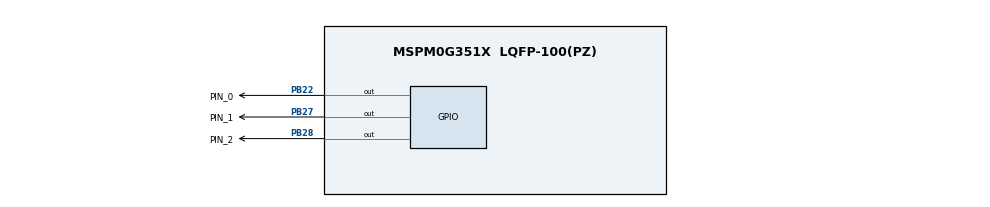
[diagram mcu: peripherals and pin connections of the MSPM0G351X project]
/**
 * @cliArgs --device "MSPM0G351X" --part "Default" --package "LQFP-100(PZ)" --product "mspm0_sdk@2.02.00.05"
 * @versions {"tool":"1.21.0+3721"}
 */

/**
 * Import the modules used in this configuration.
 */
const GPIO          = scripting.addModule("/ti/driverlib/GPIO", {}, false);
const GPIO1         = GPIO.addInstance();
const SYSCTL        = scripting.addModule("/ti/driverlib/SYSCTL");
const TIMER         = scripting.addModule("/ti/driverlib/TIMER", {}, false);
const TIMER1        = TIMER.addInstance();
const ProjectConfig = scripting.addModule("/ti/project_config/ProjectConfig");

/**
 * Write custom configuration values to the imported modules.
 */
GPIO1.$name                         = "GPIO_GRP_0";
GPIO1.associatedPins.create(3);
GPIO1.associatedPins[0].$name       = "PIN_0";
GPIO1.associatedPins[0].pin.$assign = "PB22";
GPIO1.associatedPins[1].$name       = "PIN_1";
GPIO1.associatedPins[1].pin.$assign = "PB27";
GPIO1.associatedPins[2].$name       = "PIN_2";
GPIO1.associatedPins[2].pin.$assign = "PB28";

const Board = scripting.addModule("/ti/driverlib/Board", {}, false);


TIMER1.$name            = "TIMER_0";
TIMER1.timerMode        = "PERIODIC";
TIMER1.timerClkPrescale = 32;
TIMER1.timerClkDiv      = 8;
TIMER1.timerPeriod      = "250 ms";
TIMER1.timerStartTimer  = true;
TIMER1.interrupts       = ["ZERO"];

ProjectConfig.deviceSpin = "MSPM0G3519";
ProjectConfig.genLinker  = false;
scripting.suppress("All four File Generation options must be enabled in order to guarantee Device Migration support\\. If an option is disabled, the user must manually configure that setting on its own file\\.", ProjectConfig);

/**
 * Pinmux solution for unlocked pins/peripherals. This ensures that minor changes to the automatic solver in a future
 * version of the tool will not impact the pinmux you originally saw.  These lines can be completely deleted in order to
 * re-solve from scratch.
 */
Board.peripheral.$suggestSolution          = "DEBUGSS";
Board.peripheral.swclkPin.$suggestSolution = "PA20";
Board.peripheral.swdioPin.$suggestSolution = "PA19";
SYSCTL.peripheral.$suggestSolution         = "SYSCTL";
TIMER1.peripheral.$suggestSolution         = "TIMA0";
